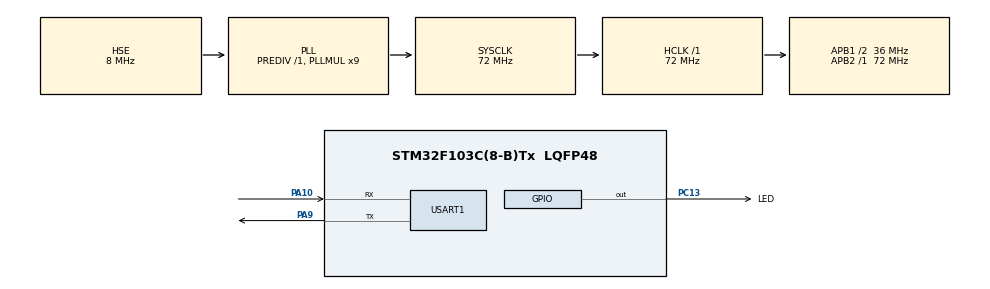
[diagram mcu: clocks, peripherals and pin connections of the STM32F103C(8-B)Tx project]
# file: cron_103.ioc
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Mcu.Family=STM32F1
Mcu.Name=STM32F103C(8-B)Tx
Mcu.Package=LQFP48
NVIC.PriorityGroup=NVIC_PRIORITYGROUP_4
NVIC.RTC_Alarm_IRQn=true\:0\:0\:false\:false\:true\:true\:true\:true
NVIC.TIM4_IRQn=true\:15\:0\:false\:false\:true\:false\:true\:true
NVIC.TimeBase=TIM4_IRQn
NVIC.TimeBaseIP=TIM4
PA10.Mode=Asynchronous
PA10.Signal=USART1_RX
PA13.Mode=Trace_Asynchronous_SW
PA13.Signal=SYS_JTMS-SWDIO
PA14.Mode=Trace_Asynchronous_SW
PA14.Signal=SYS_JTCK-SWCLK
PA9.Mode=Asynchronous
PA9.Signal=USART1_TX
PB3.Mode=Trace_Asynchronous_SW
PB3.Signal=SYS_JTDO-TRACESWO
PC13-TAMPER-RTC.GPIO_Label=LED
PC13-TAMPER-RTC.PinState=GPIO_PIN_RESET
PC13-TAMPER-RTC.Signal=GPIO_Output
PD0-OSC_IN.Mode=HSE-External-Oscillator
PD0-OSC_IN.Signal=RCC_OSC_IN
PD1-OSC_OUT.Mode=HSE-External-Oscillator
PD1-OSC_OUT.Signal=RCC_OSC_OUT
ProjectManager.HeapSize=0x200
ProjectManager.StackSize=0x400
ProjectManager.TargetToolchain=STM32CubeIDE
RCC.AHBFreq_Value=72000000
RCC.APB1CLKDivider=RCC_HCLK_DIV2
RCC.APB1Freq_Value=36000000
RCC.APB1TimFreq_Value=72000000
RCC.APB2Freq_Value=72000000
RCC.APB2TimFreq_Value=72000000
RCC.HCLKFreq_Value=72000000
RCC.PLLMUL=RCC_PLL_MUL9
RCC.PLLSourceVirtual=RCC_PLLSOURCE_HSE
RCC.SYSCLKFreq_VALUE=72000000
RCC.SYSCLKSource=RCC_SYSCLKSOURCE_PLLCLK
RCC.USBFreq_Value=72000000
RTC.Hours=13
RTC.Minutes=5
RTC.Month=RTC_MONTH_APRIL
RTC.WeekDay=RTC_WEEKDAY_SATURDAY
RTC.Year=23
USART1.VirtualMode=VM_ASYNC
VP_RTC_VS_RTC_Activate.Mode=RTC_Enabled
VP_RTC_VS_RTC_Calendar.Mode=RTC_Calendar
VP_SYS_VS_tim4.Mode=TIM4
board=custom

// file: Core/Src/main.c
/* USER CODE BEGIN Header */
/**
 ******************************************************************************
 * @file           : main.c
 * @brief          : Main program body
 ******************************************************************************
 * @attention
 *
 * Copyright (c) 2023 STMicroelectronics.
 * All rights reserved.
 *
 * This software is licensed under terms that can be found in the LICENSE file
 * in the root directory of this software component.
 * If no LICENSE file comes with this software, it is provided AS-IS.
 *
 ******************************************************************************
 */
/* USER CODE END Header */
#include "main.h"

/* USER CODE BEGIN Includes */
/*------------- Crone ---------------*/
#include <time.h>
#include <stdio.h> /* для printf */
#include "lwdtc.h"
struct tm *timez;
time_t cronetime;
time_t cronetime_old;
lwdtc_cron_ctx_t cron_ctx = { 0 };
int i = 0;
extern struct dcCron dcCrontxt[MAXSIZE];
/*--------- End crone -------------*/
/* USER CODE END Includes */

RTC_HandleTypeDef hrtc;

UART_HandleTypeDef huart1;

/* USER CODE BEGIN PV */
RTC_TimeTypeDef sTime = { 0 };
RTC_DateTypeDef sDate = { 0 };
/* USER CODE END PV */

void SystemClock_Config(void);
static void MX_GPIO_Init(void);
static void MX_RTC_Init(void);
static void MX_USART1_UART_Init(void);
/* USER CODE BEGIN PFP */
int _write(int file, char *ptr, int len) {
	int i;
	HAL_UART_Transmit(&huart1, (uint8_t*) ptr, len, 50);
	for (i = 0; i < len; i++) {
		ITM_SendChar(*ptr++);
	}
	return len;
}
/* USER CODE END PFP */

int main(void)
{

  /* MCU Configuration--------------------------------------------------------*/

  /* Reset of all peripherals, Initializes the Flash interface and the Systick. */
  HAL_Init();

  /* Configure the system clock */
  SystemClock_Config();

  /* Initialize all configured peripherals */
  MX_GPIO_Init();
  MX_RTC_Init();
  MX_USART1_UART_Init();
  /* USER CODE BEGIN 2 */
	printf("Hello world! \r\n");
  /* USER CODE END 2 */

  /* Infinite loop */
  /* USER CODE BEGIN WHILE */
	/* Set array of context objects */
	static lwdtc_cron_ctx_t cron_ctxs[MAXSIZE];

	/* Define context for CRON, used to parse data to */
	size_t fail_index;

	printf("Count task %d\r\n", LWDTC_ARRAYSIZE(dcCrontxt));
	/* Parse all cron strings */
	if (lwdtc_cron_parse_multi(cron_ctxs, dcCrontxt, MAXSIZE, &fail_index)
			!= lwdtcOK) {
		printf("Failed to parse cron at index %d\r\n", (int) fail_index);
	}
	printf("CRONs parsed and ready to go\r\n");
	/**************************************************/
	struct tm stm;

	while (1) {
    /* USER CODE END WHILE */

    /* USER CODE BEGIN 3 */
		HAL_RTC_GetTime(&hrtc, &sTime, RTC_FORMAT_BIN);
		HAL_RTC_GetDate(&hrtc, &sDate, RTC_FORMAT_BIN);

		stm.tm_year = sDate.Year + 100; //RTC_Year rang 0-99,but tm_year since 1900
		stm.tm_mon = sDate.Month - 1; //RTC_Month rang 1-12,but tm_mon rang 0-11
		stm.tm_mday = sDate.Date; //RTC_Date rang 1-31 and tm_mday rang 1-31
		stm.tm_hour = sTime.Hours;   //RTC_Hours rang 0-23 and tm_hour rang 0-23
		stm.tm_min = sTime.Minutes; //RTC_Minutes rang 0-59 and tm_min rang 0-59
		stm.tm_sec = sTime.Seconds;
		cronetime = mktime(&stm);

		if (cronetime != cronetime_old) {
			cronetime_old = cronetime;
			timez = localtime(&cronetime);
			;
			i = 0;

			/* Check if CRON should execute */
			while (i < LWDTC_ARRAYSIZE(cron_ctxs)) {
				if (lwdtc_cron_is_valid_for_time(timez, cron_ctxs, &i)
						== lwdtcOK) {
					printf("Executing CRON task %s ACTIVE %s ID %d \r\n",
							dcCrontxt[i].cron, dcCrontxt[i].activ, i);
					if(i==0){
					//HAL_GPIO_TogglePin(LED_GPIO_Port, LED_Pin);
					GPIOC->ODR ^= GPIO_PIN_13; // toggle PA1
					}
				}
				i++;
			}
		}
	}
  /* USER CODE END 3 */
}

void SystemClock_Config(void)
{
  RCC_OscInitTypeDef RCC_OscInitStruct = {0};
  RCC_ClkInitTypeDef RCC_ClkInitStruct = {0};
  RCC_PeriphCLKInitTypeDef PeriphClkInit = {0};

  /** Initializes the RCC Oscillators according to the specified parameters
  * in the RCC_OscInitTypeDef structure.
  */
  RCC_OscInitStruct.OscillatorType = RCC_OSCILLATORTYPE_LSI|RCC_OSCILLATORTYPE_HSE;
  RCC_OscInitStruct.HSEState = RCC_HSE_ON;
  RCC_OscInitStruct.HSEPredivValue = RCC_HSE_PREDIV_DIV1;
  RCC_OscInitStruct.HSIState = RCC_HSI_ON;
  RCC_OscInitStruct.LSIState = RCC_LSI_ON;
  RCC_OscInitStruct.PLL.PLLState = RCC_PLL_ON;
  RCC_OscInitStruct.PLL.PLLSource = RCC_PLLSOURCE_HSE;
  RCC_OscInitStruct.PLL.PLLMUL = RCC_PLL_MUL9;
  if (HAL_RCC_OscConfig(&RCC_OscInitStruct) != HAL_OK)
  {
    Error_Handler();
  }

  /** Initializes the CPU, AHB and APB buses clocks
  */
  RCC_ClkInitStruct.ClockType = RCC_CLOCKTYPE_HCLK|RCC_CLOCKTYPE_SYSCLK
                              |RCC_CLOCKTYPE_PCLK1|RCC_CLOCKTYPE_PCLK2;
  RCC_ClkInitStruct.SYSCLKSource = RCC_SYSCLKSOURCE_PLLCLK;
  RCC_ClkInitStruct.AHBCLKDivider = RCC_SYSCLK_DIV1;
  RCC_ClkInitStruct.APB1CLKDivider = RCC_HCLK_DIV2;
  RCC_ClkInitStruct.APB2CLKDivider = RCC_HCLK_DIV1;

  if (HAL_RCC_ClockConfig(&RCC_ClkInitStruct, FLASH_LATENCY_2) != HAL_OK)
  {
    Error_Handler();
  }
  PeriphClkInit.PeriphClockSelection = RCC_PERIPHCLK_RTC;
  PeriphClkInit.RTCClockSelection = RCC_RTCCLKSOURCE_LSI;
  if (HAL_RCCEx_PeriphCLKConfig(&PeriphClkInit) != HAL_OK)
  {
    Error_Handler();
  }
}

static void MX_RTC_Init(void)
{

  RTC_TimeTypeDef sTime = {0};
  RTC_DateTypeDef DateToUpdate = {0};

  /** Initialize RTC Only
  */
  hrtc.Instance = RTC;
  hrtc.Init.AsynchPrediv = RTC_AUTO_1_SECOND;
  hrtc.Init.OutPut = RTC_OUTPUTSOURCE_ALARM;
  if (HAL_RTC_Init(&hrtc) != HAL_OK)
  {
    Error_Handler();
  }

  /** Initialize RTC and set the Time and Date
  */
  sTime.Hours = 0x13;
  sTime.Minutes = 0x5;
  sTime.Seconds = 0x0;

  if (HAL_RTC_SetTime(&hrtc, &sTime, RTC_FORMAT_BCD) != HAL_OK)
  {
    Error_Handler();
  }
  DateToUpdate.WeekDay = RTC_WEEKDAY_SATURDAY;
  DateToUpdate.Month = RTC_MONTH_APRIL;
  DateToUpdate.Date = 0x1;
  DateToUpdate.Year = 0x23;

  if (HAL_RTC_SetDate(&hrtc, &DateToUpdate, RTC_FORMAT_BCD) != HAL_OK)
  {
    Error_Handler();
  }

}

static void MX_USART1_UART_Init(void)
{

  huart1.Instance = USART1;
  huart1.Init.BaudRate = 115200;
  huart1.Init.WordLength = UART_WORDLENGTH_8B;
  huart1.Init.StopBits = UART_STOPBITS_1;
  huart1.Init.Parity = UART_PARITY_NONE;
  huart1.Init.Mode = UART_MODE_TX_RX;
  huart1.Init.HwFlowCtl = UART_HWCONTROL_NONE;
  huart1.Init.OverSampling = UART_OVERSAMPLING_16;
  if (HAL_UART_Init(&huart1) != HAL_OK)
  {
    Error_Handler();
  }

}

static void MX_GPIO_Init(void)
{
  GPIO_InitTypeDef GPIO_InitStruct = {0};

  /* GPIO Ports Clock Enable */
  __HAL_RCC_GPIOC_CLK_ENABLE();
  __HAL_RCC_GPIOD_CLK_ENABLE();
  __HAL_RCC_GPIOA_CLK_ENABLE();
  __HAL_RCC_GPIOB_CLK_ENABLE();

  /*Configure GPIO pin Output Level */
  HAL_GPIO_WritePin(LED_GPIO_Port, LED_Pin, GPIO_PIN_RESET);

  /*Configure GPIO pin : LED_Pin */
  GPIO_InitStruct.Pin = LED_Pin;
  GPIO_InitStruct.Mode = GPIO_MODE_OUTPUT_PP;
  GPIO_InitStruct.Pull = GPIO_NOPULL;
  GPIO_InitStruct.Speed = GPIO_SPEED_FREQ_LOW;
  HAL_GPIO_Init(LED_GPIO_Port, &GPIO_InitStruct);

}

void HAL_TIM_PeriodElapsedCallback(TIM_HandleTypeDef *htim)
{
  if (htim->Instance == TIM4) {
    HAL_IncTick();
  }
}

void Error_Handler(void)
{
	__disable_irq();
	while (1) {
	}
}
